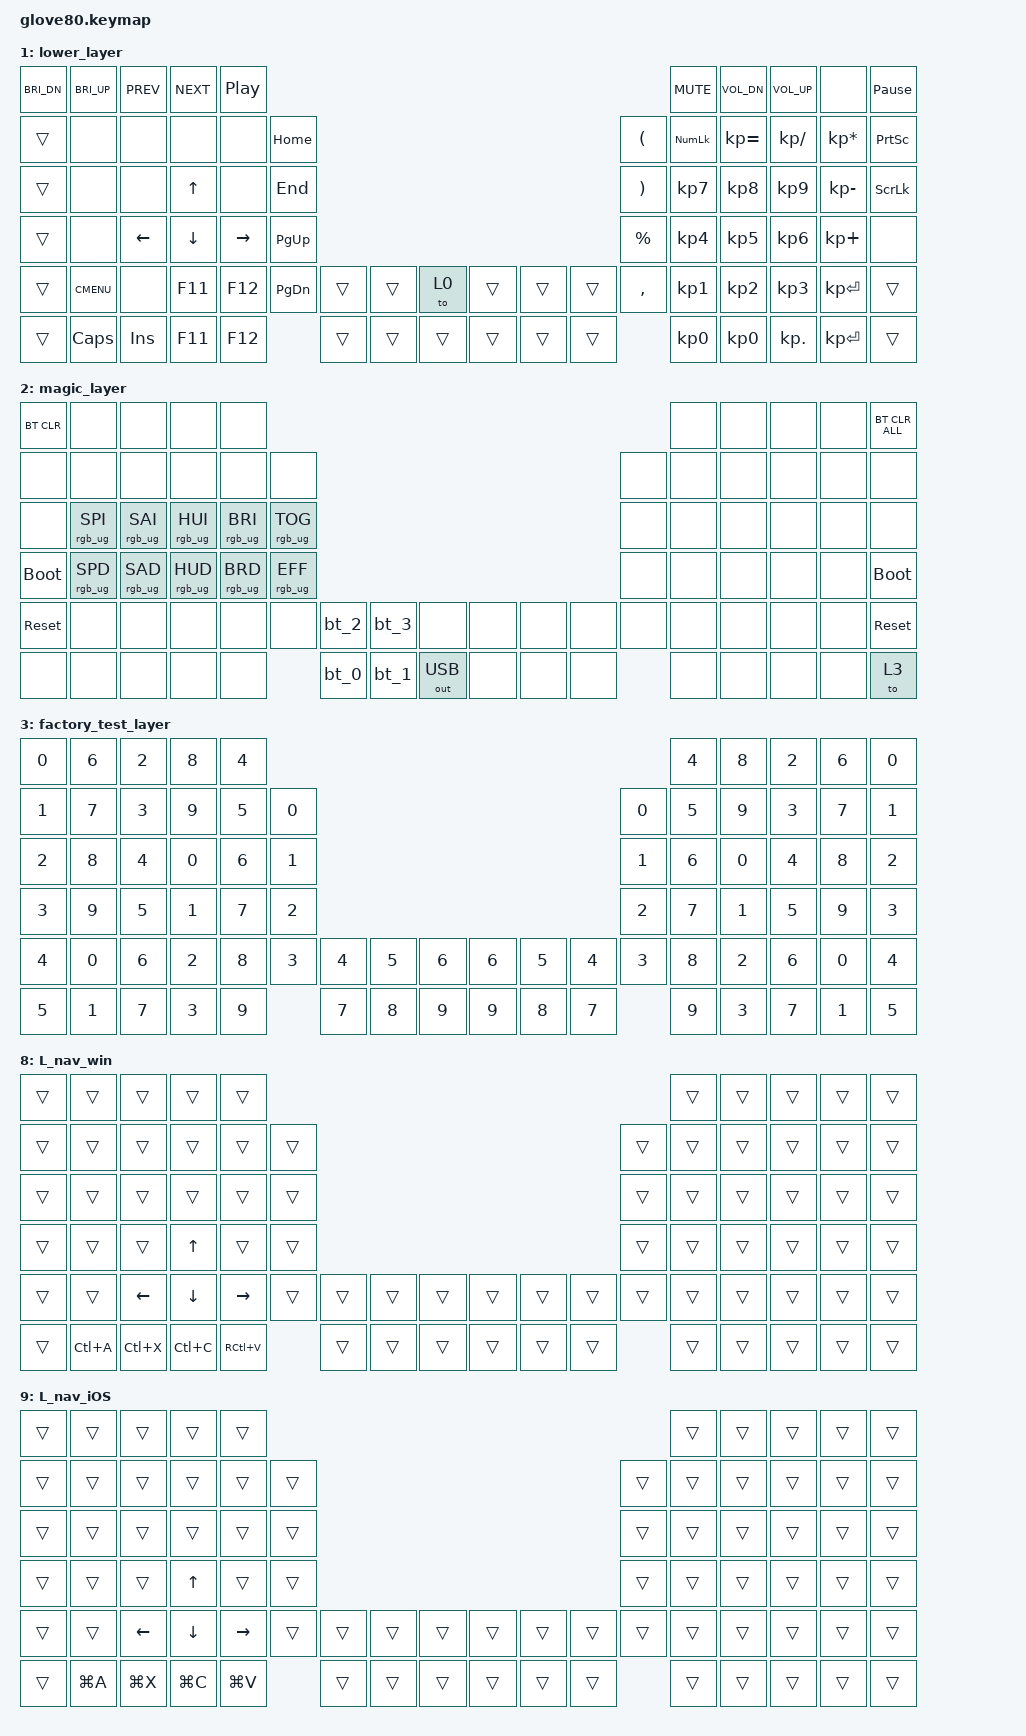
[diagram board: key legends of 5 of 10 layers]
/*
 * Copyright (c) 2020 The ZMK Contributors
 *
 * SPDX-License-Identifier: MIT
 */

#include <behaviors.dtsi>
#include <dt-bindings/zmk/bt.h>
#include <dt-bindings/zmk/keys.h>
#include <dt-bindings/zmk/mouse.h>
#include <dt-bindings/zmk/outputs.h>
#include <dt-bindings/zmk/rgb.h>

#define HYPER LC(LS(LG(LALT)))

// layers

#define DEFAULT 0
#define LOWER 1
#define MAGIC 2
#define FACTORY_TEST 3

/ {
    behaviors {
        // For the "layer" key, it'd nice to be able to use it as either a shift or a toggle.
        // Configure it as a tap dance, so the first tap (or hold) is a &mo and the second tap is a &to

        layer_td: tap_dance_0 {
            compatible = "zmk,behavior-tap-dance";
            label = "LAYER_TAP_DANCE";
            #binding-cells = <0>;
            tapping-term-ms = <200>;
            bindings = <&mo 1>, <&to 1>;
        };

        magic: magic_hold_tap {
            compatible = "zmk,behavior-hold-tap";
            label = "MAGIC_HOLD_TAP";
            #binding-cells = <2>;
            flavor = "tap-preferred";
            tapping-term-ms = <200>;
            bindings = <&mo>, <&rgb_ug_status_macro>;
        };
    };

    macros {
        rgb_ug_status_macro: rgb_ug_status_macro_0 {
            label = "RGB_UG_STATUS";
            compatible = "zmk,behavior-macro";
            #binding-cells = <0>;
            bindings = <&rgb_ug RGB_STATUS>;
        };

        bt_0: bt_profile_macro_0 {
            label = "BT_0";
            compatible = "zmk,behavior-macro";
            #binding-cells = <0>;
            bindings = <&out OUT_BLE &bt BT_SEL 0>;
        };

        bt_1: bt_profile_macro_1 {
            label = "BT_1";
            compatible = "zmk,behavior-macro";
            #binding-cells = <0>;
            bindings = <&out OUT_BLE &bt BT_SEL 1>;
        };

        bt_2: bt_profile_macro_2 {
            label = "BT_2";
            compatible = "zmk,behavior-macro";
            #binding-cells = <0>;
            bindings = <&out OUT_BLE &bt BT_SEL 2>;
        };

        bt_3: bt_profile_macro_3 {
            label = "BT_3";
            compatible = "zmk,behavior-macro";
            #binding-cells = <0>;
            bindings = <&out OUT_BLE &bt BT_SEL 3>;
        };

        boldItalics: boldItalics {
            compatible = "zmk,behavior-macro";
            #binding-cells = <0>;
            bindings = <&kp LC(B) &kp LC(I)>;
            label = "BOLDITALICS";
        };
    };

    combos {
        compatible = "zmk,combos";

        Enter_R {
            bindings = <&kp ENTER>;
            key-positions = <42 41>;
        };

        EnterShift_R {
            bindings = <&kp RS(ENTER)>;
            key-positions = <59 60>;
        };

        backspc_R {
            bindings = <&kp DELETE>;
            key-positions = <75 76>;
        };

        delete_r {
            bindings = <&kp DELETE>;
            key-positions = <76 77>;
        };

        base {
            bindings = <&to 0>;
            key-positions = <43 42>;
        };

        maya {
            bindings = <&to 6>;
            key-positions = <30 31 29>;
        };

        nav {
            bindings = <&to 4>;
            key-positions = <60 61>;
        };

        numpad {
            bindings = <&to 5>;
            key-positions = <76 75 77>;
        };

        maya_lefthand {
            bindings = <&to 7>;
            key-positions = <30 31>;
        };
    };

    keymap {
        compatible = "zmk,keymap";

        default_layer {
            // ---------------------------------------------------------------------------------------------------------------------------------
            // |  F1   |  F2 |  F3 |  F4  |  F5  |                                                               |  F6   |  F7   |  F8  |   F9  |  F10 |
            // |  =    |  1  |  2  |  3   |  4   |  5   |                                                 |  6   |   7   |   8   |  9   |   0   |   -  |
            // |  TAB  |  Q  |  W  |  E   |  R   |  T   |                                                 |  Y   |   U   |   I   |  O   |   P   |   \  |
            // |  ESC  |  A  |  S  |  D   |  F   |  G   |                                                 |  H   |   J   |   K   |  L   |   ;   |   '  |
            // |   `   |  Z  |  X  |  C   |  V   |  B   | LSHFT | LCTRL | LOWER | | LGUI  | RCTRL | RSHFT |  N   |   M   |   ,   |  .   |   /   | PGUP |
            // | MAGIC | HOME| END | LEFT | RIGHT|      | BSPC  | DEL   | LALT  | | RALT  | RET   | SPACE |      |  UP   | DOWN  |  [   |   ]   | PGDN |

            bindings = <
&kp F1      &kp F2         &kp F3       &kp F4    &rgb_ug RGB_COLOR_HSB(287,100,29)                                                                                                                   &kp F6        &kp F7          &kp F8      &to 6                &kp F11
&kp GRAVE   &kp N1         &kp N2       &kp N3    &kp N4                             &kp N5                                                                                                   &kp N6  &kp N7        &kp N8          &kp N9      &kp NUMBER_0         &kp EQUAL
&kp ESCAPE  &kp Q          &kp W        &kp E     &kp R                              &kp T                                                                                                    &kp Y   &kp U         &kp I           &kp O       &kp P                &kp MINUS
&kp TAB     &kp A          &kp S        &kp D     &kp F                              &kp G                                                                                                    &kp H   &kp J         &kp K           &kp L       &mt SLASH RS(SLASH)  &mt RS(APOSTROPHE) APOSTROPHE
&kp CAPS    &kp A          &kp X        &kp C     &kp V                              &kp B   &kp LEFT_CONTROL  &kp LEFT_GUI   &mo 9  &to 5         &to 4                      &kp LEFT_SHIFT  &kp B   &kp N         &kp M           &kp COMMA   &mt SEMI RS(SEMI)    &kp RIGHT_BRACKET
&magic 2 0  &kp RIGHT_ALT  &mt LC(Z) Z  &kp LEFT  &kp RIGHT                                  &kp LEFT_SHIFT    &kp BACKSPACE  &mo 8  &lt 4 DELETE  &mt RIGHT_SHIFT BACKSPACE  &kp SPACE               &kp UP_ARROW  &kp DOWN_ARROW  &kp PERIOD  &kp LEFT_BRACKET     &kp ENTER
            >;
        };

        lower_layer {
            bindings = <
&kp C_BRI_DN  &kp C_BRI_UP  &kp C_PREV  &kp C_NEXT  &kp C_PP                                                                         &kp C_MUTE  &kp C_VOL_DN  &kp C_VOL_UP   &none            &kp PAUSE_BREAK
&trans        &none         &none       &none       &none      &kp HOME                                                   &kp LPAR   &kp KP_NUM  &kp KP_EQUAL  &kp KP_DIVIDE  &kp KP_MULTIPLY  &kp PSCRN
&trans        &none         &none       &kp UP      &none      &kp END                                                    &kp RPAR   &kp KP_N7   &kp KP_N8     &kp KP_N9      &kp KP_MINUS     &kp SLCK
&trans        &none         &kp LEFT    &kp DOWN    &kp RIGHT  &kp PG_UP                                                  &kp PRCNT  &kp KP_N4   &kp KP_N5     &kp KP_N6      &kp KP_PLUS      &none
&trans        &kp K_CMENU   &none       &kp F11     &kp F12    &kp PG_DN  &trans  &trans  &to 0   &trans  &trans  &trans  &kp COMMA  &kp KP_N1   &kp KP_N2     &kp KP_N3      &kp KP_ENTER     &trans
&trans        &kp CAPS      &kp INS     &kp F11     &kp F12               &trans  &trans  &trans  &trans  &trans  &trans             &kp KP_N0   &kp KP_N0     &kp KP_DOT     &kp KP_ENTER     &trans
            >;
        };

        magic_layer {
            bindings = <
&bt BT_CLR   &none            &none            &none            &none                                                                                     &none  &none  &none  &none  &bt BT_CLR_ALL
&none        &none            &none            &none            &none            &none                                                             &none  &none  &none  &none  &none  &none
&none        &rgb_ug RGB_SPI  &rgb_ug RGB_SAI  &rgb_ug RGB_HUI  &rgb_ug RGB_BRI  &rgb_ug RGB_TOG                                                   &none  &none  &none  &none  &none  &none
&bootloader  &rgb_ug RGB_SPD  &rgb_ug RGB_SAD  &rgb_ug RGB_HUD  &rgb_ug RGB_BRD  &rgb_ug RGB_EFF                                                   &none  &none  &none  &none  &none  &bootloader
&sys_reset   &none            &none            &none            &none            &none            &bt_2  &bt_3  &none         &none  &none  &none  &none  &none  &none  &none  &none  &sys_reset
&none        &none            &none            &none            &none                             &bt_0  &bt_1  &out OUT_USB  &none  &none  &none         &none  &none  &none  &none  &to 3
            >;
        };

        factory_test_layer {
            bindings = <
&kp N0  &kp N6  &kp N2  &kp N8  &kp N4                                                                  &kp N4  &kp N8  &kp N2  &kp N6  &kp N0
&kp N1  &kp N7  &kp N3  &kp N9  &kp N5  &kp N0                                                  &kp N0  &kp N5  &kp N9  &kp N3  &kp N7  &kp N1
&kp N2  &kp N8  &kp N4  &kp N0  &kp N6  &kp N1                                                  &kp N1  &kp N6  &kp N0  &kp N4  &kp N8  &kp N2
&kp N3  &kp N9  &kp N5  &kp N1  &kp N7  &kp N2                                                  &kp N2  &kp N7  &kp N1  &kp N5  &kp N9  &kp N3
&kp N4  &kp N0  &kp N6  &kp N2  &kp N8  &kp N3  &kp N4  &kp N5  &kp N6  &kp N6  &kp N5  &kp N4  &kp N3  &kp N8  &kp N2  &kp N6  &kp N0  &kp N4
&kp N5  &kp N1  &kp N7  &kp N3  &kp N9          &kp N7  &kp N8  &kp N9  &kp N9  &kp N8  &kp N7          &kp N9  &kp N3  &kp N7  &kp N1  &kp N5
            >;
        };

        nav {
            bindings = <
&trans     &trans        &trans          &trans          &none                                                                                                                                                   &trans          &trans          &trans           &trans           &trans
&trans     &trans        &trans          &trans          &trans           &rgb_ug RGB_COLOR_HSB(230,100,23)                                                                   &trans                             &trans          &trans          &trans           &trans           &trans
&trans     &trans        &trans          &kp UP_ARROW    &trans           &trans                                                                                              &rgb_ug RGB_COLOR_HSB(243,100,22)  &trans          &kp UP_ARROW    &trans           &kp PRINTSCREEN  &kp F11
&trans     &kp LEFT_WIN  &kp LEFT_ARROW  &kp DOWN_ARROW  &kp RIGHT_ARROW  &trans                                                                                              &trans                             &kp LEFT_ARROW  &kp DOWN_ARROW  &kp RIGHT_ARROW  &kp LGUI         &trans
&kp LC(Z)  &kp LC(A)     &kp LC(X)       &kp LC(C)       &kp LC(V)        &boldItalics                       &trans          &trans  &trans  &trans  &trans  &trans           &kp RC(A)                          &kp RC(X)       &kp RC(C)       &kp RC(V)        &boldItalics     &kp RC(Z)
&trans     &kp LG(A)     &kp LG(X)       &kp LG(C)       &kp LG(V)                                           &kp LEFT_SHIFT  &trans  &to 0   &to 0   &trans  &kp RIGHT_SHIFT                                     &kp RG(A)       &kp RG(X)       &kp RG(C)        &kp RG(V)        &trans
            >;
        };

        numpad {
            bindings = <
&trans  &trans    &trans     &trans  &none                                                                                                                    &trans          &kp UP_ARROW  &trans           &trans      &trans
&trans  &trans    &trans     &trans  &trans   &rgb_ug RGB_COLOR_HSB(61,100,27)                                                                    &trans      &kp LEFT_ARROW  &kp DOWN      &kp RIGHT_ARROW  &trans      &trans
&trans  &kp BSPC  &kp N7     &kp N8  &kp N9   &trans                                                                                              &trans      &kp N7          &kp N8        &kp N9           &kp BSPC    &trans
&trans  &kp DEL   &kp N4     &kp N5  &kp N6   &kp LS(N8)                                                                                          &kp RS(N8)  &kp N4          &kp N5        &kp N6           &kp DELETE  &trans
&trans  &trans    &kp N1     &kp N2  &kp N3   &kp EQUAL                         &kp LC(A)  &kp LC(C)  &kp LC(V)  &kp RC(A)  &kp RC(C)  &kp RC(V)  &kp EQUAL   &kp N1          &kp N2        &kp N3           &trans      &trans
&trans  &to 0     &kp MINUS  &kp N0  &kp DOT                                    &kp RSHFT  &kp ENTER  &to 0      &to 0      &trans     &kp RSHFT              &kp DOT         &kp N0        &kp MINUS        &to 6       &kp ENTER
            >;
        };

        Maya {
            bindings = <
&trans  &trans  &trans       &trans  &none                                                                                                                                             &trans               &kp UP_ARROW               &trans           &to 0                &kp F8
&trans  &trans  &trans       &trans  &trans  &rgb_ug RGB_COLOR_HSB(124,100,27)                                                                                               &to 5     &kp LEFT_ARROW       &kp DOWN_ARROW             &kp RIGHT_ARROW  &kp DELETE           &kp F11
&trans  &trans  &trans       &trans  &trans  &trans                                                                                                                          &mkp MB2  &mt RA(N1) NUMBER_1  &mt RA(NUMBER_2) NUMBER_2  &kp N3           &mt N4 RA(NUMBER_4)  &kp BSLH
&trans  &trans  &mt Q RA(Q)  &trans  &trans  &kp DELETE                                                                                                                      &mkp MB3  &mt RA(W) W          &kp E                      &kp R            &kp MINUS            &kp EQUAL
&trans  &trans  &kp U        &kp J   &kp K   &trans                             &mt Q RA(Q)  &trans         &to 5             &kp SPACE  &kp LC(RA(V))  &kp RA(RIGHT_SHIFT)  &mkp MB1  &kp S                &kp X                      &kp C            &kp LBKT             &kp RBKT
&trans  &trans  &trans       &trans  &trans                                     &kp LC(S)    &kp LC(LS(S))  &kp LEFT_CONTROL  &kp LA(V)  &kp LSHFT      &kp RALT                       &kp RSHFT            &kp RC(Z)                  &kp RC(Y)        &kp LEFT_CONTROL     &kp RIGHT_CONTROL
            >;
        };

        maya_Lhand {
            bindings = <
&kp F8         &kp A            &kp F                      &kp UP_ARROW               &none                                                                                                                         &trans          &trans          &trans           &trans   &trans
&kp F11        &kp PRINTSCREEN  &kp LEFT_ARROW             &kp DOWN_ARROW             &kp RIGHT_ARROW  &rgb_ug RGB_COLOR_HSB(185,100,29)                                                                    &trans  &trans          &trans          &trans           &kp DEL  &trans
&kp BACKSLASH  &trans           &mt LA(NUMBER_1) NUMBER_1  &mt LA(NUMBER_2) NUMBER_2  &kp NUMBER_3     &mt NUMBER_4 LA(NUMBER_4)                                                                            &kp U   &kp J           &kp K           &trans           &trans   &trans
&kp MINUS      &kp EQUAL        &kp W                      &kp E                      &kp R            &kp RA(W)                                                                                            &trans  &trans          &kp UP_ARROW    &kp RA(Q)        &trans   &trans
&kp LBKT       &kp RBKT         &kp LC(X)                  &kp LC(C)                  &kp S            &kp S                              &kp X     &kp C      &kp SPACE  &trans  &kp LC(S)  &kp RS(LC(S))  &trans  &kp LEFT_ARROW  &kp DOWN_ARROW  &kp RIGHT_ARROW  &trans   &trans
&trans         &kp LCTRL        &kp LC(Z)                  &kp LC(Y)                  &kp RSHFT                                           &kp RALT  &kp RC(Z)  &kp LC(Y)  &trans  &trans     &trans                 &trans          &trans          &trans           &trans   &trans
            >;
        };

        L_nav_win {
            bindings = <
&trans  &trans     &trans          &trans          &trans                                                                           &trans  &trans  &trans  &trans  &trans
&trans  &trans     &trans          &trans          &trans           &trans                                                  &trans  &trans  &trans  &trans  &trans  &trans
&trans  &trans     &trans          &trans          &trans           &trans                                                  &trans  &trans  &trans  &trans  &trans  &trans
&trans  &trans     &trans          &kp UP_ARROW    &trans           &trans                                                  &trans  &trans  &trans  &trans  &trans  &trans
&trans  &trans     &kp LEFT_ARROW  &kp DOWN_ARROW  &kp RIGHT_ARROW  &trans  &trans  &trans  &trans  &trans  &trans  &trans  &trans  &trans  &trans  &trans  &trans  &trans
&trans  &kp LC(A)  &kp LC(X)       &kp LC(C)       &kp RC(V)                &trans  &trans  &trans  &trans  &trans  &trans          &trans  &trans  &trans  &trans  &trans
            >;
        };

        L_nav_iOS {
            bindings = <
&trans  &trans     &trans          &trans          &trans                                                                           &trans  &trans  &trans  &trans  &trans
&trans  &trans     &trans          &trans          &trans           &trans                                                  &trans  &trans  &trans  &trans  &trans  &trans
&trans  &trans     &trans          &trans          &trans           &trans                                                  &trans  &trans  &trans  &trans  &trans  &trans
&trans  &trans     &trans          &kp UP_ARROW    &trans           &trans                                                  &trans  &trans  &trans  &trans  &trans  &trans
&trans  &trans     &kp LEFT_ARROW  &kp DOWN_ARROW  &kp RIGHT_ARROW  &trans  &trans  &trans  &trans  &trans  &trans  &trans  &trans  &trans  &trans  &trans  &trans  &trans
&trans  &kp LG(A)  &kp LG(X)       &kp LG(C)       &kp LG(V)                &trans  &trans  &trans  &trans  &trans  &trans          &trans  &trans  &trans  &trans  &trans
            >;
        };
    };
};
